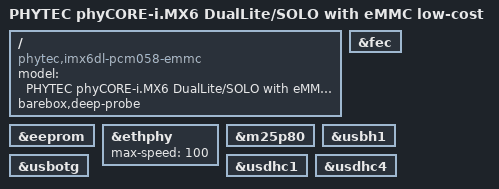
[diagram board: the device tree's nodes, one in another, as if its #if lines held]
// SPDX-License-Identifier: (GPL-2.0-or-later OR MIT)
/*
 * Copyright (C) 2019 PHYTEC Messtechnik GmbH,
 * Author: Stefan Riedmueller <s.riedmueller@phytec.de>
 */

/dts-v1/;
#ifdef CONFIG_BOOTM_FITIMAGE_PUBKEY
#include CONFIG_BOOTM_FITIMAGE_PUBKEY
#endif
#include <arm/nxp/imx/imx6dl.dtsi>
#include "imx6dl.dtsi"
#include "imx6qdl-phytec-phycore-som.dtsi"
#include "imx6qdl-phytec-mira.dtsi"
#include "imx6qdl-phytec-state.dtsi"

/ {
	model = "PHYTEC phyCORE-i.MX6 DualLite/SOLO with eMMC low-cost";
	compatible = "phytec,imx6dl-pcm058-emmc", "fsl,imx6dl";
	barebox,deep-probe;
};

&eeprom {
	status = "okay";
};

&ethphy {
	max-speed = <100>;
};

&fec {
	status = "okay";
};

&m25p80 {
	status = "okay";
};

&usbh1 {
	status = "okay";
};

&usbotg {
	status = "okay";
};

&usdhc1 {
	status = "okay";
};

&usdhc4 {
	status = "okay";
};
